VERSION "HIPBNYYYYYYYYYYYYYYYYYYYYYYYYYYYYYYYYYYYYY/4/%%%/4/'%**4YYY///"

NS_ :

BS_:

BU_: RMS_PM_Controller

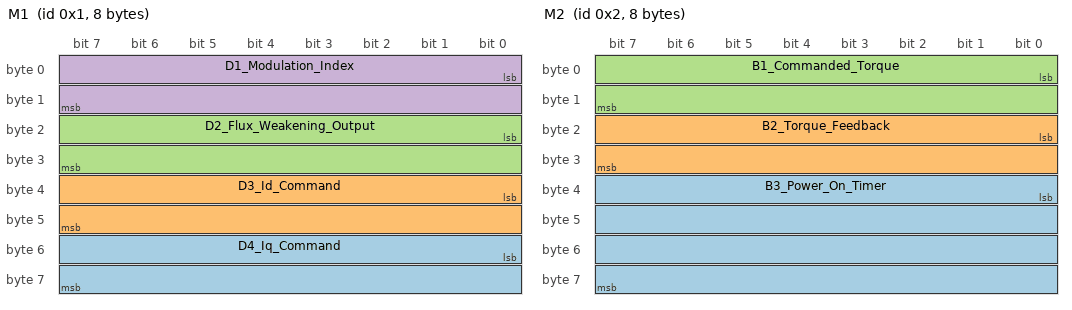
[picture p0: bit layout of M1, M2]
BO_ 1 M1: 8 RMS_PM_Controller
 SG_ D4_Iq_Command : 48|16@1- (0.1,0) [-3276.8|3276.7] "A" Vector__XXX
 SG_ D3_Id_Command : 32|16@1- (0.1,0) [-3276.8|3276.7] "A" Vector__XXX
 SG_ D2_Flux_Weakening_Output : 16|16@1- (0.1,0) [-3276.8|3276.7] "A" Vector__XXX
 SG_ D1_Modulation_Index : 0|16@1+ (0.01,0) [0|0] "" Vector__XXX

BO_ 2 M2: 8 RMS_PM_Controller
 SG_ B3_Power_On_Timer : 32|32@1+ (0.003,0) [0|4.29497e+009] "Sec" Vector__XXX
 SG_ B2_Torque_Feedback : 16|16@1- (0.1,0) [-3276.8|3276.7] "Nm" Vector__XXX
 SG_ B1_Commanded_Torque : 0|16@1- (0.1,0) [-3276.8|3276.7] "Nm" Vector__XXX

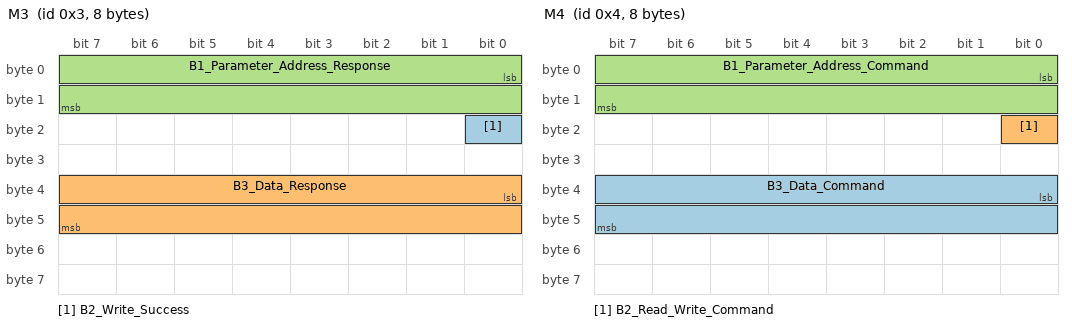
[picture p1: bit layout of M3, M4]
BO_ 3 M3: 8 RMS_PM_Controller
 SG_ B2_Write_Success : 16|1@1+ (1,0) [0|1] "" Vector__XXX
 SG_ B3_Data_Response : 32|16@1- (1,0) [-32768|32767] "" Vector__XXX
 SG_ B1_Parameter_Address_Response : 0|16@1+ (1,0) [0|65535] "" Vector__XXX

BO_ 4 M4: 8 Vector__XXX
 SG_ B3_Data_Command : 32|16@1- (1,0) [-32768|32767] "" Vector__XXX
 SG_ B2_Read_Write_Command : 16|1@1+ (1,0) [0|1] "" Vector__XXX
 SG_ B1_Parameter_Address_Command : 0|16@1+ (1,0) [0|65535] "" Vector__XXX

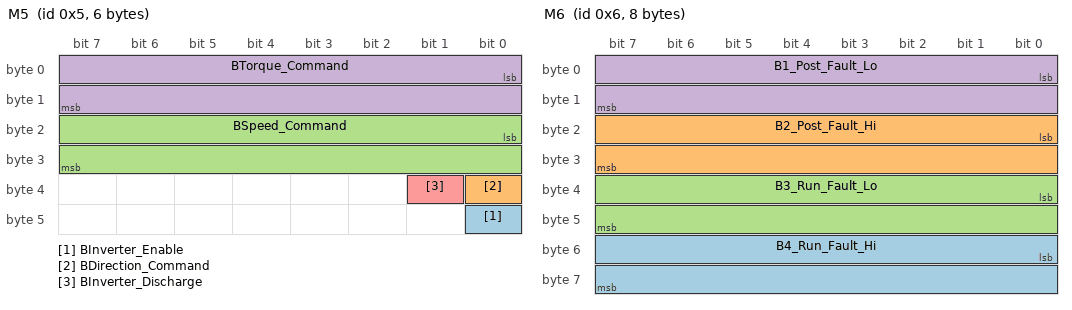
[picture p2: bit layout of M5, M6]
BO_ 5 M5: 6 Vector__XXX
 SG_ BInverter_Enable : 40|1@1+ (1,0) [0|1] "Bit" Vector__XXX
 SG_ BDirection_Command : 32|1@1+ (1,0) [0|1] "Bit" Vector__XXX
 SG_ BSpeed_Command : 16|16@1- (1,0) [-32768|32767] "rpm" Vector__XXX
 SG_ BTorque_Command : 0|16@1- (0.1,0) [-3276.8|3276.7] "Nm" Vector__XXX
 SG_ BInverter_Discharge : 33|1@1+ (1,0) [0|1] "Bit" Vector__XXX

BO_ 6 M6: 8 RMS_PM_Controller
 SG_ B4_Run_Fault_Hi : 48|16@1+ (1,0) [0|65535] "" Vector__XXX
 SG_ B2_Post_Fault_Hi : 16|16@1+ (1,0) [0|65535] "" Vector__XXX
 SG_ B3_Run_Fault_Lo : 32|16@1+ (1,0) [0|65535] "" Vector__XXX
 SG_ B1_Post_Fault_Lo : 0|16@1+ (1,0) [0|65535] "" Vector__XXX

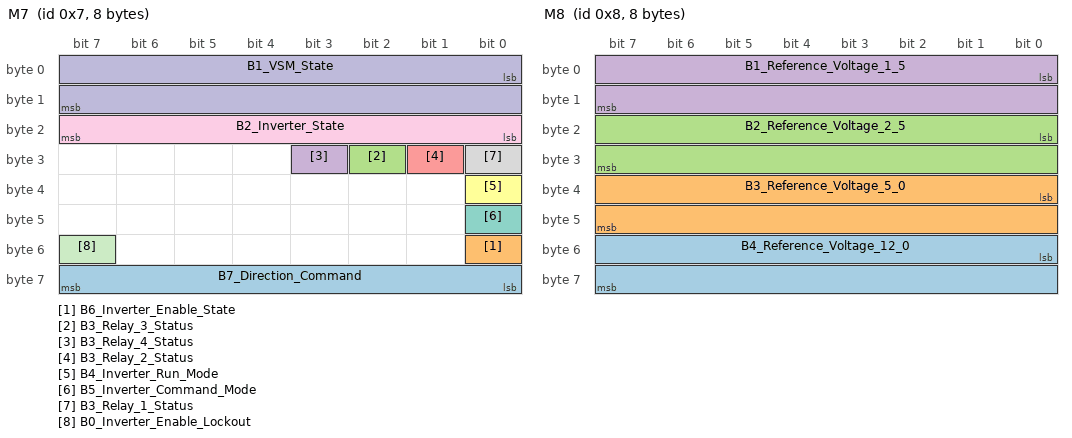
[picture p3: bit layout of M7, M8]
BO_ 7 M7: 8 RMS_PM_Controller
 SG_ B7_Direction_Command : 56|8@1+ (1,0) [0|1] "" Vector__XXX
 SG_ B6_Inverter_Enable_State : 48|1@1+ (1,0) [0|1] "" Vector__XXX
 SG_ B3_Relay_3_Status : 26|1@1+ (1,0) [0|1] "" Vector__XXX
 SG_ B3_Relay_4_Status : 27|1@1+ (1,0) [0|1] "" Vector__XXX
 SG_ B3_Relay_2_Status : 25|1@1+ (1,0) [0|1] "" Vector__XXX
 SG_ B4_Inverter_Run_Mode : 32|1@1+ (1,0) [0|1] "" Vector__XXX
 SG_ B5_Inverter_Command_Mode : 40|1@1+ (1,0) [0|1] "" Vector__XXX
 SG_ B3_Relay_1_Status : 24|1@1+ (1,0) [0|1] "" Vector__XXX
 SG_ B2_Inverter_State : 16|8@1+ (1,0) [0|255] "" Vector__XXX
 SG_ B1_VSM_State : 0|16@1+ (1,0) [0|15] "" Vector__XXX
 SG_ B0_Inverter_Enable_Lockout : 55|1@1+ (1,0) [0|1] "" Vector__XXX

BO_ 8 M8: 8 RMS_PM_Controller
 SG_ B4_Reference_Voltage_12_0 : 48|16@1- (0.01,0) [-327.68|327.67] "V" Vector__XXX
 SG_ B3_Reference_Voltage_5_0 : 32|16@1- (0.01,0) [-327.68|327.67] "V" Vector__XXX
 SG_ B2_Reference_Voltage_2_5 : 16|16@1- (0.01,0) [-327.68|327.67] "V" Vector__XXX
 SG_ B1_Reference_Voltage_1_5 : 0|16@1- (0.01,0) [-327.68|327.67] "V" Vector__XXX

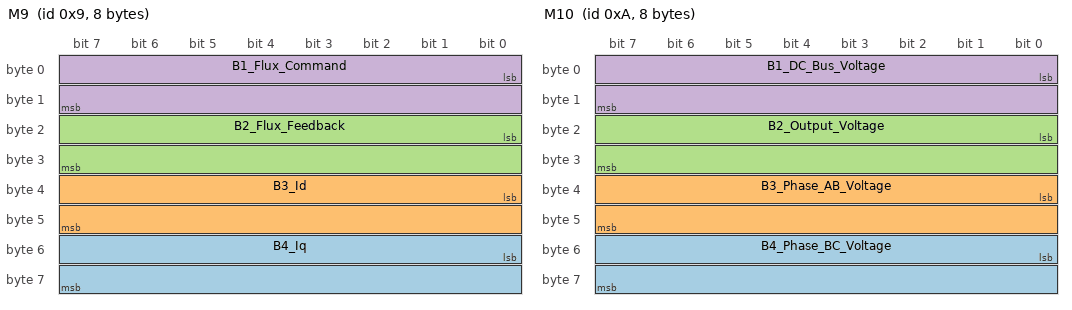
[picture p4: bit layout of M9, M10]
BO_ 9 M9: 8 RMS_PM_Controller
 SG_ B4_Iq : 48|16@1- (0.1,0) [-3276.8|3276.7] "A" Vector__XXX
 SG_ B3_Id : 32|16@1- (0.1,0) [-3276.8|3276.7] "A" Vector__XXX
 SG_ B2_Flux_Feedback : 16|16@1- (0.001,0) [-32.768|32.767] "Wb" Vector__XXX
 SG_ B1_Flux_Command : 0|16@1- (0.001,0) [-32.768|32.767] "Wb" Vector__XXX

BO_ 10 M10: 8 RMS_PM_Controller
 SG_ B4_Phase_BC_Voltage : 48|16@1- (0.1,0) [-3276.8|3276.7] "V" Vector__XXX
 SG_ B3_Phase_AB_Voltage : 32|16@1- (0.1,0) [-3276.8|3276.7] "V" Vector__XXX
 SG_ B2_Output_Voltage : 16|16@1- (0.1,0) [-3276.8|3276.7] "V" Vector__XXX
 SG_ B1_DC_Bus_Voltage : 0|16@1- (0.1,0) [-3276.8|3276.7] "V" Vector__XXX

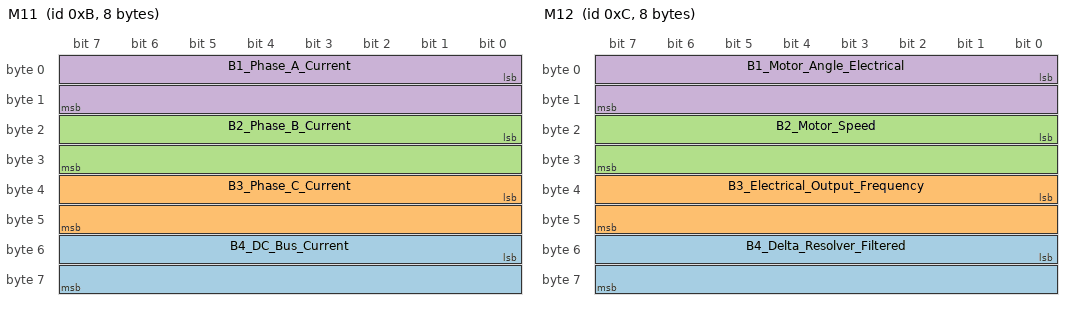
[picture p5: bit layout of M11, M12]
BO_ 11 M11: 8 RMS_PM_Controller
 SG_ B4_DC_Bus_Current : 48|16@1- (0.1,0) [-3276.8|3276.7] "A" Vector__XXX
 SG_ B3_Phase_C_Current : 32|16@1- (0.1,0) [-3276.8|3276.7] "A" Vector__XXX
 SG_ B2_Phase_B_Current : 16|16@1- (0.1,0) [-3276.8|3276.7] "A" Vector__XXX
 SG_ B1_Phase_A_Current : 0|16@1- (0.1,0) [-3276.8|3276.7] "A" Vector__XXX

BO_ 12 M12: 8 RMS_PM_Controller
 SG_ B4_Delta_Resolver_Filtered : 48|16@1- (0.1,0) [-3276.8|3276.7] "deg" Vector__XXX
 SG_ B3_Electrical_Output_Frequency : 32|16@1- (0.1,0) [-3276.8|3276.7] "hz" Vector__XXX
 SG_ B2_Motor_Speed : 16|16@1- (1,0) [-32768|32767] "rpm" Vector__XXX
 SG_ B1_Motor_Angle_Electrical : 0|16@1+ (0.1,0) [0|6553.5] "deg" Vector__XXX

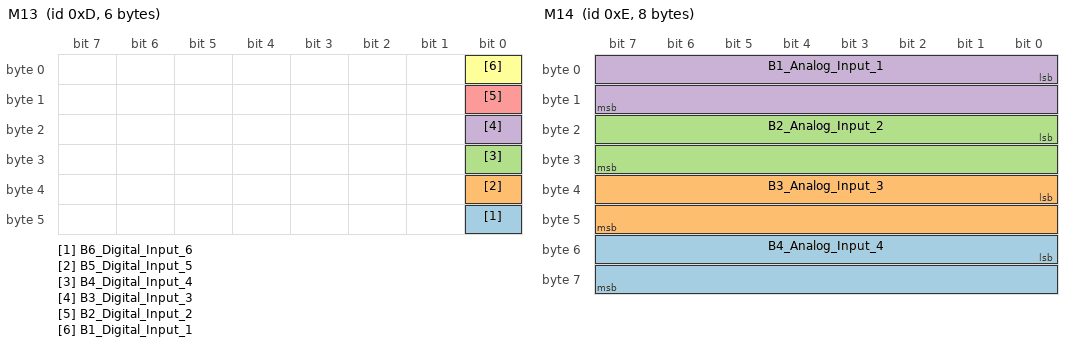
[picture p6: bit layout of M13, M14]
BO_ 13 M13: 6 RMS_PM_Controller
 SG_ B6_Digital_Input_6 : 40|1@1+ (1,0) [0|1] "boolean" Vector__XXX
 SG_ B5_Digital_Input_5 : 32|1@1+ (1,0) [0|1] "boolean" Vector__XXX
 SG_ B4_Digital_Input_4 : 24|1@1+ (1,0) [0|1] "boolean" Vector__XXX
 SG_ B3_Digital_Input_3 : 16|1@1+ (1,0) [0|1] "boolean" Vector__XXX
 SG_ B2_Digital_Input_2 : 8|1@1+ (1,0) [0|1] "boolean" Vector__XXX
 SG_ B1_Digital_Input_1 : 0|1@1+ (1,0) [0|1] "boolean" Vector__XXX

BO_ 14 M14: 8 RMS_PM_Controller
 SG_ B4_Analog_Input_4 : 48|16@1- (0.01,0) [-327.68|327.67] "V" Vector__XXX
 SG_ B3_Analog_Input_3 : 32|16@1- (0.01,0) [-327.68|327.67] "V" Vector__XXX
 SG_ B2_Analog_Input_2 : 16|16@1- (0.01,0) [-327.68|327.67] "V" Vector__XXX
 SG_ B1_Analog_Input_1 : 0|16@1- (0.01,0) [-327.68|327.67] "V" Vector__XXX

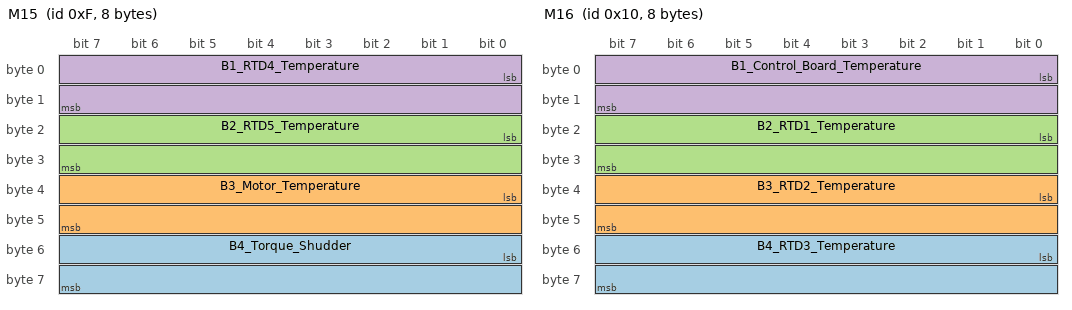
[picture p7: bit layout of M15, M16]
BO_ 15 M15: 8 RMS_PM_Controller
 SG_ B4_Torque_Shudder : 48|16@1- (0.1,0) [-3276.8|3276.7] "Nm" Vector__XXX
 SG_ B3_Motor_Temperature : 32|16@1- (0.1,0) [-3276.8|3276.7] "degC" Vector__XXX
 SG_ B2_RTD5_Temperature : 16|16@1- (0.1,0) [-3276.8|3276.7] "degC" Vector__XXX
 SG_ B1_RTD4_Temperature : 0|16@1- (0.1,0) [-3276.8|3276.7] "degC" Vector__XXX

BO_ 16 M16: 8 RMS_PM_Controller
 SG_ B4_RTD3_Temperature : 48|16@1- (0.1,0) [-3276.8|3276.7] "degC" Vector__XXX
 SG_ B3_RTD2_Temperature : 32|16@1- (0.1,0) [-3276.8|3276.7] "degC" Vector__XXX
 SG_ B2_RTD1_Temperature : 16|16@1- (0.1,0) [-3276.8|3276.7] "degC" Vector__XXX
 SG_ B1_Control_Board_Temperature : 0|16@1- (0.1,0) [-3276.8|3276.7] "degC" Vector__XXX

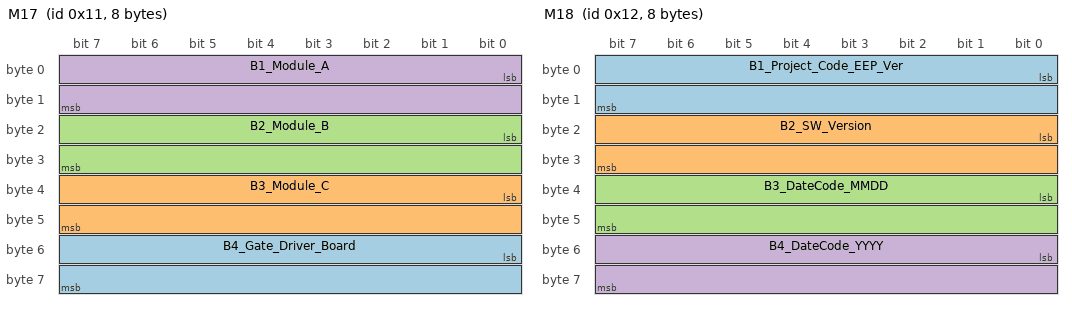
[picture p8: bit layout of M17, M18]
BO_ 17 M17: 8 RMS_PM_Controller
 SG_ B4_Gate_Driver_Board : 48|16@1- (0.1,0) [-3276.8|3276.7] "degC" Vector__XXX
 SG_ B3_Module_C : 32|16@1- (0.1,0) [-3276.8|3276.7] "degC" Vector__XXX
 SG_ B2_Module_B : 16|16@1- (0.1,0) [-3276.8|3276.7] "degC" Vector__XXX
 SG_ B1_Module_A : 0|16@1- (0.1,0) [-3276.8|3276.7] "degC" Vector__XXX

BO_ 18 M18: 8 RMS_PM_Controller
 SG_ B1_Project_Code_EEP_Ver : 0|16@1+ (1,0) [0|65535] "" Vector__XXX
 SG_ B2_SW_Version : 16|16@1+ (1,0) [0|65535] "" Vector__XXX
 SG_ B3_DateCode_MMDD : 32|16@1+ (1,0) [0|65535] "" Vector__XXX
 SG_ B4_DateCode_YYYY : 48|16@1+ (1,0) [0|65535] "" Vector__XXX

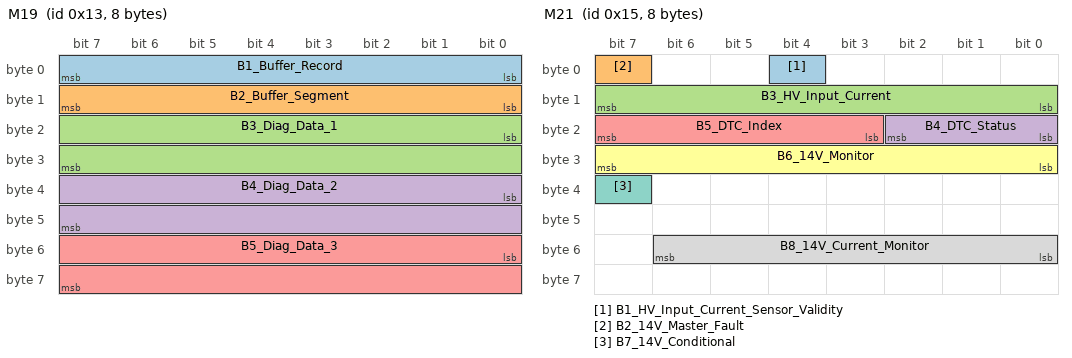
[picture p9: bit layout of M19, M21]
BO_ 19 M19: 8 RMS_PM_Controller
 SG_ B1_Buffer_Record : 0|8@1+ (1,0) [0|160] "" Vector__XXX
 SG_ B2_Buffer_Segment : 8|8@1+ (1,0) [0|5] "" Vector__XXX
 SG_ B3_Diag_Data_1 : 16|16@1- (1,0) [0|65535] "" Vector__XXX
 SG_ B4_Diag_Data_2 : 32|16@1- (1,0) [0|65535] "" Vector__XXX
 SG_ B5_Diag_Data_3 : 48|16@1- (1,0) [0|65535] "" Vector__XXX

BO_ 20 M20: 8 RMS_PM_Controller
 SG_ B1_ID_Byte : 0|8@1+ (1,0) [0|255] "" Vector__XXX
 SG_ B2_Setpoint_Calc : 8|8@1+ (1,0) [0|255] "" Vector__XXX

BO_ 21 M21: 8 Vector__XXX
 SG_ B1_HV_Input_Current_Sensor_Validity : 4|1@1+ (1,0) [0|1] "" Vector__XXX
 SG_ B2_14V_Master_Fault : 7|1@1+ (1,0) [0|1] "" Vector__XXX
 SG_ B3_HV_Input_Current : 8|8@1+ (1,0) [0|255] "" Vector__XXX
 SG_ B4_DTC_Status : 16|3@1+ (1,0) [0|7] "" Vector__XXX
 SG_ B5_DTC_Index : 19|5@1+ (1,0) [0|31] "" Vector__XXX
 SG_ B6_14V_Monitor : 24|8@1+ (1,0) [0|255] "" Vector__XXX
 SG_ B7_14V_Conditional : 39|1@1+ (1,0) [0|1] "" Vector__XXX
 SG_ B8_14V_Current_Monitor : 48|7@1+ (1,0) [0|127] "" Vector__XXX

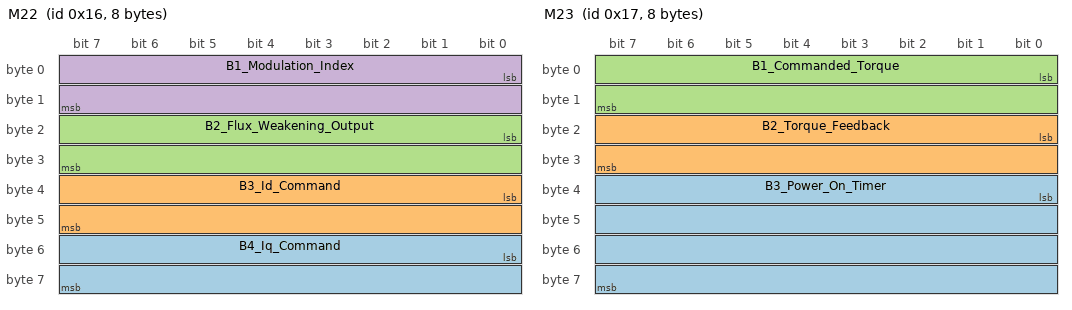
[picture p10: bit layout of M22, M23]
BO_ 22 M22: 8 RMS_PM_Controller
 SG_ B4_Iq_Command : 48|16@1- (0.1,0) [-3276.8|3276.7] "A" Vector__XXX
 SG_ B3_Id_Command : 32|16@1- (0.1,0) [-3276.8|3276.7] "A" Vector__XXX
 SG_ B2_Flux_Weakening_Output : 16|16@1- (0.1,0) [-3276.8|3276.7] "A" Vector__XXX
 SG_ B1_Modulation_Index : 0|16@1+ (0.01,0) [0|0] "" Vector__XXX

BO_ 23 M23: 8 RMS_PM_Controller
 SG_ B3_Power_On_Timer : 32|32@1+ (0.003,0) [0|4.29497e+009] "Sec" Vector__XXX
 SG_ B2_Torque_Feedback : 16|16@1- (0.1,0) [-3276.8|3276.7] "Nm" Vector__XXX
 SG_ B1_Commanded_Torque : 0|16@1- (0.1,0) [-3276.8|3276.7] "Nm" Vector__XXX

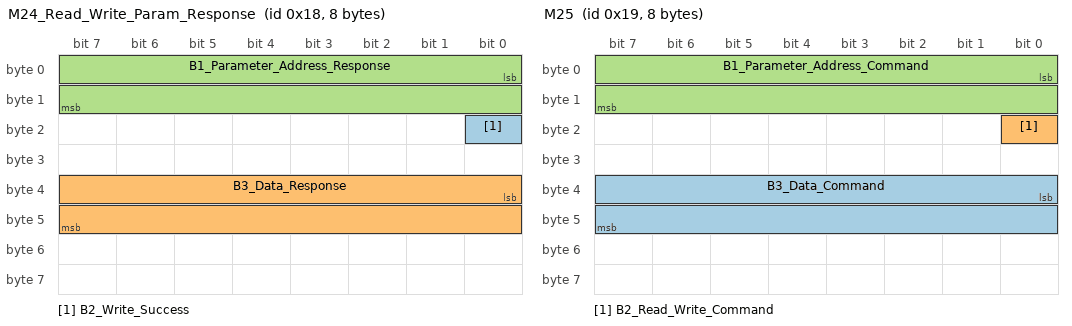
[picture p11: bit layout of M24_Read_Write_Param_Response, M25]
BO_ 24 M24_Read_Write_Param_Response: 8 RMS_PM_Controller
 SG_ B2_Write_Success : 16|1@1+ (1,0) [0|1] "" Vector__XXX
 SG_ B3_Data_Response : 32|16@1- (1,0) [-32768|32767] "" Vector__XXX
 SG_ B1_Parameter_Address_Response : 0|16@1+ (1,0) [0|65535] "" Vector__XXX

BO_ 25 M25: 8 Vector__XXX
 SG_ B3_Data_Command : 32|16@1- (1,0) [-32768|32767] "" Vector__XXX
 SG_ B2_Read_Write_Command : 16|1@1+ (1,0) [0|1] "" Vector__XXX
 SG_ B1_Parameter_Address_Command : 0|16@1+ (1,0) [0|65535] "" Vector__XXX

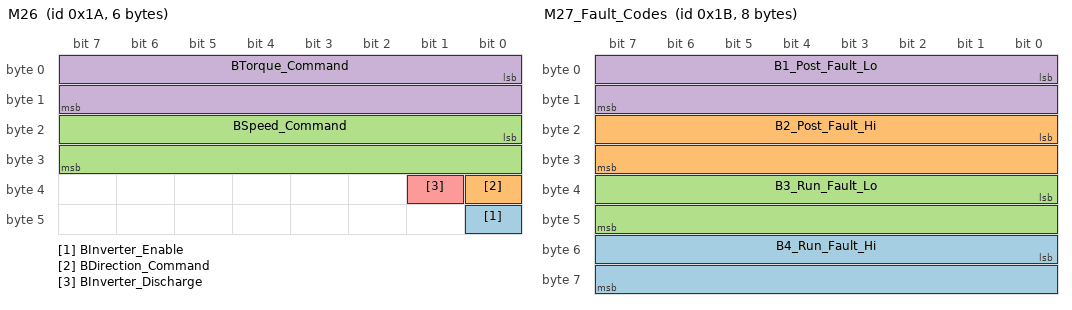
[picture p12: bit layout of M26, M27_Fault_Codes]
BO_ 26 M26: 6 Vector__XXX
 SG_ BInverter_Enable : 40|1@1+ (1,0) [0|1] "Bit" Vector__XXX
 SG_ BDirection_Command : 32|1@1+ (1,0) [0|1] "Bit" Vector__XXX
 SG_ BSpeed_Command : 16|16@1- (1,0) [-32768|32767] "rpm" Vector__XXX
 SG_ BTorque_Command : 0|16@1- (0.1,0) [-3276.8|3276.7] "Nm" Vector__XXX
 SG_ BInverter_Discharge : 33|1@1+ (1,0) [0|1] "Bit" Vector__XXX

BO_ 27 M27_Fault_Codes: 8 RMS_PM_Controller
 SG_ B4_Run_Fault_Hi : 48|16@1+ (1,0) [0|65535] "" Vector__XXX
 SG_ B2_Post_Fault_Hi : 16|16@1+ (1,0) [0|65535] "" Vector__XXX
 SG_ B3_Run_Fault_Lo : 32|16@1+ (1,0) [0|65535] "" Vector__XXX
 SG_ B1_Post_Fault_Lo : 0|16@1+ (1,0) [0|65535] "" Vector__XXX

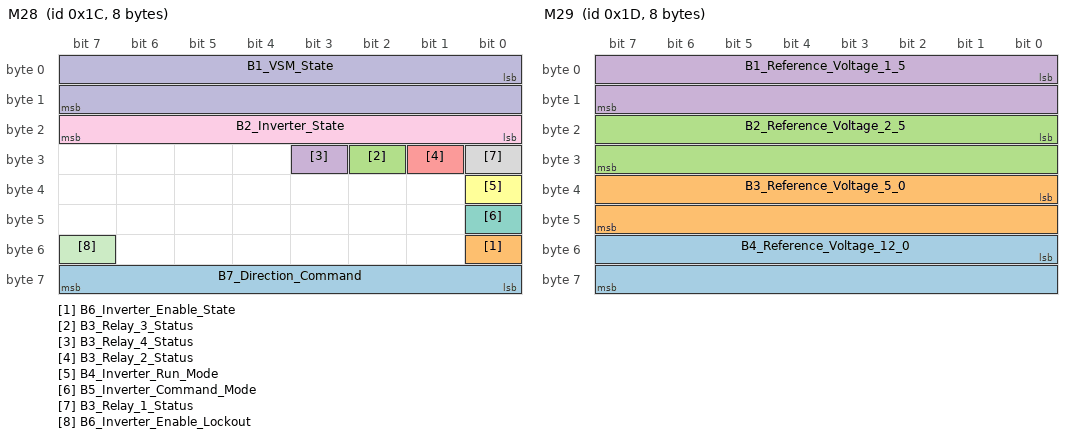
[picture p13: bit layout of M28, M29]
BO_ 28 M28: 8 RMS_PM_Controller
 SG_ B7_Direction_Command : 56|8@1+ (1,0) [0|1] "" Vector__XXX
 SG_ B6_Inverter_Enable_State : 48|1@1+ (1,0) [0|1] "" Vector__XXX
 SG_ B3_Relay_3_Status : 26|1@1+ (1,0) [0|1] "" Vector__XXX
 SG_ B3_Relay_4_Status : 27|1@1+ (1,0) [0|1] "" Vector__XXX
 SG_ B3_Relay_2_Status : 25|1@1+ (1,0) [0|1] "" Vector__XXX
 SG_ B4_Inverter_Run_Mode : 32|1@1+ (1,0) [0|1] "" Vector__XXX
 SG_ B5_Inverter_Command_Mode : 40|1@1+ (1,0) [0|1] "" Vector__XXX
 SG_ B3_Relay_1_Status : 24|1@1+ (1,0) [0|1] "" Vector__XXX
 SG_ B2_Inverter_State : 16|8@1+ (1,0) [0|255] "" Vector__XXX
 SG_ B1_VSM_State : 0|16@1+ (1,0) [0|15] "" Vector__XXX
 SG_ B6_Inverter_Enable_Lockout : 55|1@1+ (1,0) [0|1] "" Vector__XXX

BO_ 29 M29: 8 RMS_PM_Controller
 SG_ B4_Reference_Voltage_12_0 : 48|16@1- (0.01,0) [-327.68|327.67] "V" Vector__XXX
 SG_ B3_Reference_Voltage_5_0 : 32|16@1- (0.01,0) [-327.68|327.67] "V" Vector__XXX
 SG_ B2_Reference_Voltage_2_5 : 16|16@1- (0.01,0) [-327.68|327.67] "V" Vector__XXX
 SG_ B1_Reference_Voltage_1_5 : 0|16@1- (0.01,0) [-327.68|327.67] "V" Vector__XXX

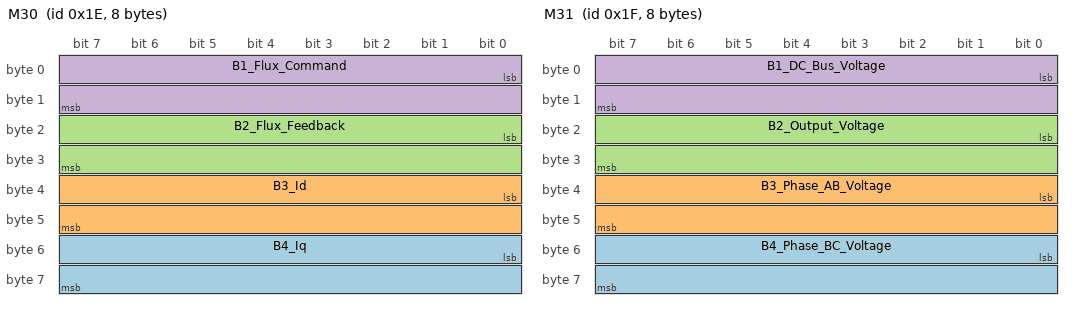
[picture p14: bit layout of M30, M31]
BO_ 30 M30: 8 RMS_PM_Controller
 SG_ B4_Iq : 48|16@1- (0.1,0) [-3276.8|3276.7] "A" Vector__XXX
 SG_ B3_Id : 32|16@1- (0.1,0) [-3276.8|3276.7] "A" Vector__XXX
 SG_ B2_Flux_Feedback : 16|16@1- (0.001,0) [-32.768|32.767] "Wb" Vector__XXX
 SG_ B1_Flux_Command : 0|16@1- (0.001,0) [-32.768|32.767] "Wb" Vector__XXX

BO_ 31 M31: 8 RMS_PM_Controller
 SG_ B4_Phase_BC_Voltage : 48|16@1- (0.1,0) [-3276.8|3276.7] "V" Vector__XXX
 SG_ B3_Phase_AB_Voltage : 32|16@1- (0.1,0) [-3276.8|3276.7] "V" Vector__XXX
 SG_ B2_Output_Voltage : 16|16@1- (0.1,0) [-3276.8|3276.7] "V" Vector__XXX
 SG_ B1_DC_Bus_Voltage : 0|16@1- (0.1,0) [-3276.8|3276.7] "V" Vector__XXX

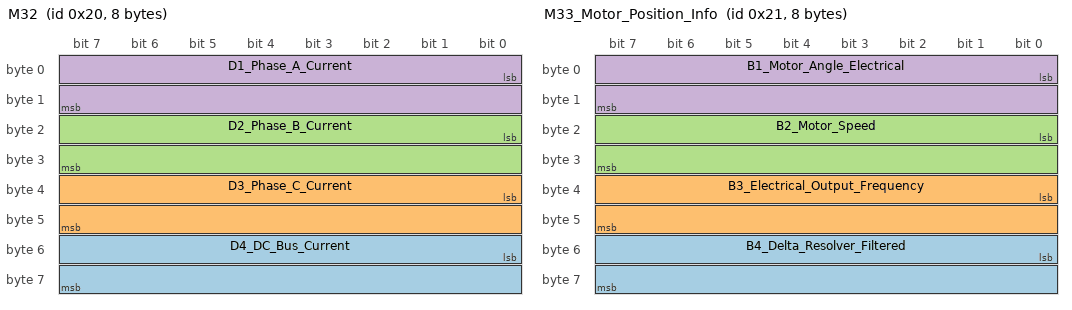
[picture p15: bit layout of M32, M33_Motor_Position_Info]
BO_ 32 M32: 8 RMS_PM_Controller
 SG_ D4_DC_Bus_Current : 48|16@1- (0.1,0) [-3276.8|3276.7] "A" Vector__XXX
 SG_ D3_Phase_C_Current : 32|16@1- (0.1,0) [-3276.8|3276.7] "A" Vector__XXX
 SG_ D2_Phase_B_Current : 16|16@1- (0.1,0) [-3276.8|3276.7] "A" Vector__XXX
 SG_ D1_Phase_A_Current : 0|16@1- (0.1,0) [-3276.8|3276.7] "A" Vector__XXX

BO_ 33 M33_Motor_Position_Info: 8 RMS_PM_Controller
 SG_ B4_Delta_Resolver_Filtered : 48|16@1- (0.1,0) [-3276.8|3276.7] "deg" Vector__XXX
 SG_ B3_Electrical_Output_Frequency : 32|16@1- (0.1,0) [-3276.8|3276.7] "hz" Vector__XXX
 SG_ B2_Motor_Speed : 16|16@1- (1,0) [-32768|32767] "rpm" Vector__XXX
 SG_ B1_Motor_Angle_Electrical : 0|16@1+ (0.1,0) [0|6553.5] "deg" Vector__XXX

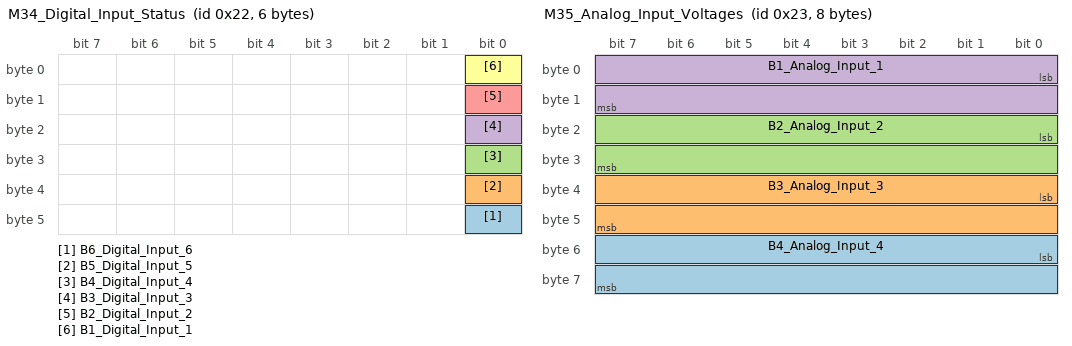
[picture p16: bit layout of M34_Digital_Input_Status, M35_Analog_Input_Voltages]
BO_ 34 M34_Digital_Input_Status: 6 RMS_PM_Controller
 SG_ B6_Digital_Input_6 : 40|1@1+ (1,0) [0|1] "boolean" Vector__XXX
 SG_ B5_Digital_Input_5 : 32|1@1+ (1,0) [0|1] "boolean" Vector__XXX
 SG_ B4_Digital_Input_4 : 24|1@1+ (1,0) [0|1] "boolean" Vector__XXX
 SG_ B3_Digital_Input_3 : 16|1@1+ (1,0) [0|1] "boolean" Vector__XXX
 SG_ B2_Digital_Input_2 : 8|1@1+ (1,0) [0|1] "boolean" Vector__XXX
 SG_ B1_Digital_Input_1 : 0|1@1+ (1,0) [0|1] "boolean" Vector__XXX

BO_ 35 M35_Analog_Input_Voltages: 8 RMS_PM_Controller
 SG_ B4_Analog_Input_4 : 48|16@1- (0.01,0) [-327.68|327.67] "V" Vector__XXX
 SG_ B3_Analog_Input_3 : 32|16@1- (0.01,0) [-327.68|327.67] "V" Vector__XXX
 SG_ B2_Analog_Input_2 : 16|16@1- (0.01,0) [-327.68|327.67] "V" Vector__XXX
 SG_ B1_Analog_Input_1 : 0|16@1- (0.01,0) [-327.68|327.67] "V" Vector__XXX

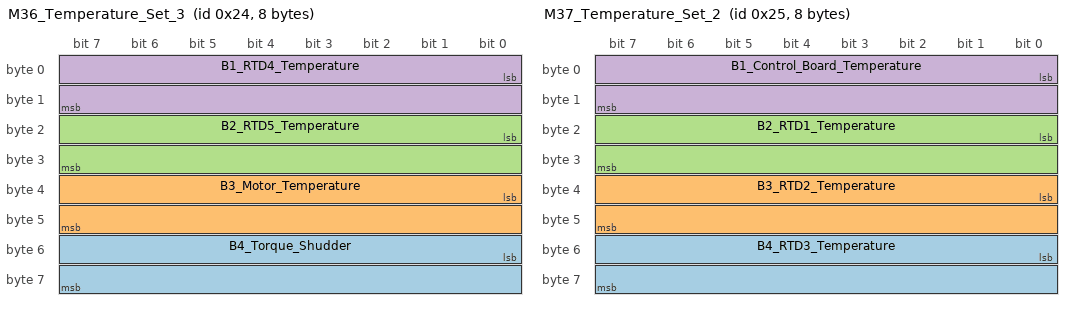
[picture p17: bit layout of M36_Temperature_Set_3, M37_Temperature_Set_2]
BO_ 36 M36_Temperature_Set_3: 8 RMS_PM_Controller
 SG_ B4_Torque_Shudder : 48|16@1- (0.1,0) [-3276.8|3276.7] "Nm" Vector__XXX
 SG_ B3_Motor_Temperature : 32|16@1- (0.1,0) [-3276.8|3276.7] "degC" Vector__XXX
 SG_ B2_RTD5_Temperature : 16|16@1- (0.1,0) [-3276.8|3276.7] "degC" Vector__XXX
 SG_ B1_RTD4_Temperature : 0|16@1- (0.1,0) [-3276.8|3276.7] "degC" Vector__XXX

BO_ 37 M37_Temperature_Set_2: 8 RMS_PM_Controller
 SG_ B4_RTD3_Temperature : 48|16@1- (0.1,0) [-3276.8|3276.7] "degC" Vector__XXX
 SG_ B3_RTD2_Temperature : 32|16@1- (0.1,0) [-3276.8|3276.7] "degC" Vector__XXX
 SG_ B2_RTD1_Temperature : 16|16@1- (0.1,0) [-3276.8|3276.7] "degC" Vector__XXX
 SG_ B1_Control_Board_Temperature : 0|16@1- (0.1,0) [-3276.8|3276.7] "degC" Vector__XXX

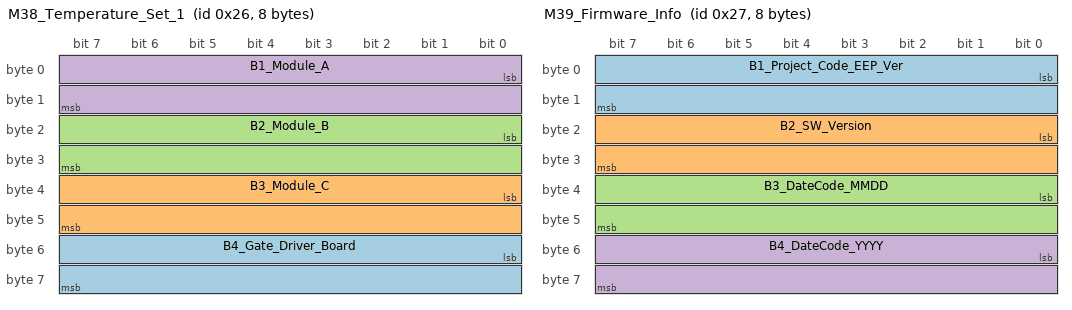
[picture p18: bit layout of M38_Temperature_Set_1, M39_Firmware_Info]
BO_ 38 M38_Temperature_Set_1: 8 RMS_PM_Controller
 SG_ B4_Gate_Driver_Board : 48|16@1- (0.1,0) [-3276.8|3276.7] "degC" Vector__XXX
 SG_ B3_Module_C : 32|16@1- (0.1,0) [-3276.8|3276.7] "degC" Vector__XXX
 SG_ B2_Module_B : 16|16@1- (0.1,0) [-3276.8|3276.7] "degC" Vector__XXX
 SG_ B1_Module_A : 0|16@1- (0.1,0) [-3276.8|3276.7] "degC" Vector__XXX

BO_ 39 M39_Firmware_Info: 8 RMS_PM_Controller
 SG_ B1_Project_Code_EEP_Ver : 0|16@1+ (1,0) [0|65535] "" Vector__XXX
 SG_ B2_SW_Version : 16|16@1+ (1,0) [0|65535] "" Vector__XXX
 SG_ B3_DateCode_MMDD : 32|16@1+ (1,0) [0|65535] "" Vector__XXX
 SG_ B4_DateCode_YYYY : 48|16@1+ (1,0) [0|65535] "" Vector__XXX

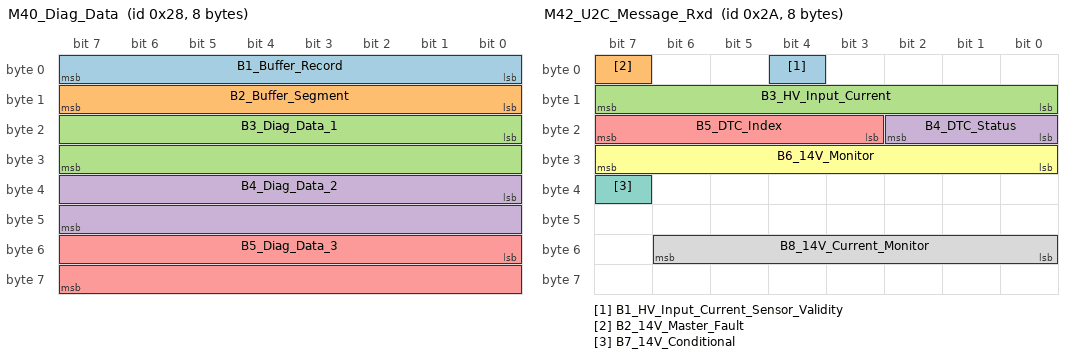
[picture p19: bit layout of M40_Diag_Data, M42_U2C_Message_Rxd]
BO_ 40 M40_Diag_Data: 8 RMS_PM_Controller
 SG_ B1_Buffer_Record : 0|8@1+ (1,0) [0|160] "" Vector__XXX
 SG_ B2_Buffer_Segment : 8|8@1+ (1,0) [0|5] "" Vector__XXX
 SG_ B3_Diag_Data_1 : 16|16@1- (1,0) [0|65535] "" Vector__XXX
 SG_ B4_Diag_Data_2 : 32|16@1- (1,0) [0|65535] "" Vector__XXX
 SG_ B5_Diag_Data_3 : 48|16@1- (1,0) [0|65535] "" Vector__XXX

BO_ 41 M41_U2C_Command_Txd: 8 RMS_PM_Controller
 SG_ B1_ID_Byte : 0|8@1+ (1,0) [0|255] "" Vector__XXX
 SG_ B2_Setpoint_Calc : 8|8@1+ (1,0) [0|255] "" Vector__XXX

BO_ 42 M42_U2C_Message_Rxd: 8 Vector__XXX
 SG_ B1_HV_Input_Current_Sensor_Validity : 4|1@1+ (1,0) [0|1] "" Vector__XXX
 SG_ B2_14V_Master_Fault : 7|1@1+ (1,0) [0|1] "" Vector__XXX
 SG_ B3_HV_Input_Current : 8|8@1+ (1,0) [0|255] "" Vector__XXX
 SG_ B4_DTC_Status : 16|3@1+ (1,0) [0|7] "" Vector__XXX
 SG_ B5_DTC_Index : 19|5@1+ (1,0) [0|31] "" Vector__XXX
 SG_ B6_14V_Monitor : 24|8@1+ (1,0) [0|255] "" Vector__XXX
 SG_ B7_14V_Conditional : 39|1@1+ (1,0) [0|1] "" Vector__XXX
 SG_ B8_14V_Current_Monitor : 48|7@1+ (1,0) [0|127] "" Vector__XXX

CM_ SG_ 173 D4_Iq_Command "The commanded Q-axis current";
CM_ SG_ 173 D3_Id_Command "The commanded D-axis current";
CM_ SG_ 173 D2_Flux_Weakening_Output "This is the current output of the flux regulator.";
CM_ SG_ 173 D1_Modulation_Index "This is the modulation index. The scale factor is x100. To get the actual modulation index divide the value by 100.";
CM_ SG_ 172 D3_Power_On_Timer "Updated every 3 msec. This will roll over in approximately 150 days!";
CM_ SG_ 172 D2_Torque_Feedback "Estimated motor torque feedback";
CM_ SG_ 172 D1_Commanded_Torque "The commanded Torque";
CM_ BO_ 194 "To write a parameter use message 0x0C1 with byte #2 set to 1 (write). 
To read a parameter use message 0x0C1 with byte #2 to set 0 (read). ";
CM_ SG_ 194 D2_Write_Success "0=Write failure, 1=Success";
CM_ SG_ 194 D3_Data_Response "All EEPROM data is 16 bits and is contained in bytes 4 and 5. Bytes 6 and 7 should be ignored.";
CM_ SG_ 194 D1_Parameter_Address_Response "Valid EEPROM Parameter CAN addresses are between 100 and 499.";
CM_ BO_ 193 "To write a parameter use message 0x0C1 with byte #2 set to 1 (write). 
To read a parameter use message 0x0C1 with byte #2 to set 0 (read). ";
CM_ SG_ 193 D3_Data_Command "All EEPROM data is 16 bits and is contained in bytes 4 and 5.";
CM_ SG_ 193 D2_Read_Write_Command "0=Read, 1=Write";
CM_ SG_ 193 D1_Parameter_Address_Command "Valid EEPROM Parameter CAN addresses are between 100 and 499.";
CM_ BO_ 192 "The command message is used to transmit data to the controller. This message is sent from a user supplied external controller to the PMxxx controller.";
CM_ SG_ 192 Inverter_Enable "0=Inverter OFF, 1 = Inverter ON";
CM_ SG_ 192 Direction_Command "0=CW, 1=CCW as veiwed from the shaft end of the motor";
CM_ SG_ 192 Speed_Command "Speed commandused when in speed mode";
CM_ SG_ 192 Torque_Command "Torque command when in torque mode";
CM_ SG_ 192 Inverter_Discharge "0=Discharge Disable,
=Discharge Enable";
CM_ SG_ 171 D4_Run_Fault_Hi "Each bit represents a fault. Please refer to PM100 Users Manual for details.";
CM_ SG_ 171 D2_Post_Fault_Hi "Each bit represents a fault. Please refer to PM100 Users Manual for details.";
CM_ SG_ 171 D3_Run_Fault_Lo "Each bit represents a fault. Please refer to PM100 Users Manual for details.";
CM_ SG_ 171 D1_Post_Fault_Lo "Each bit represents a fault. Please refer to PM100 Users Manual for details.";
CM_ SG_ 170 D7_Direction_Command "1 = Forward
0 = 'Reverse' if inverter enabled  & 'Stopped' if inverter is disabled";
CM_ SG_ 170 D6_Inverter_Enable_State "0=Inverter Disabled, 
1=Inverter Enabled";
CM_ SG_ 170 D3_Relay_3_Status "0=OFF, 1=ON";
CM_ SG_ 170 D3_Relay_4_Status "0=OFF, 1=ON";
CM_ SG_ 170 D3_Relay_2_Status "0=OFF, 1=ON";
CM_ SG_ 170 D4_Inverter_Run_Mode "0=Torque Mode, 1=Speed Mode";
CM_ SG_ 170 D5_Inverter_Command_Mode "0=CAN mode, 1=VSM mode";
CM_ SG_ 170 D3_Relay_1_Status "0=OFF, 1=ON";
CM_ SG_ 170 D2_Inverter_State "Different states for the inverter state machine";
CM_ SG_ 170 D1_VSM_State "Different states for the vehicle state machine";
CM_ SG_ 170 D6_Inverter_Enable_Lockout "0=Lockout Disabled, 1=Lockout Enabled";
CM_ SG_ 168 D2_Flux_Feedback "The estimated flux";
CM_ SG_ 168 D1_Flux_Command "The commanded flux";
CM_ SG_ 167 D4_Phase_BC_Voltage "Measured value of the voltage between Phase B and Phase C";
CM_ SG_ 167 D3_Phase_AB_Voltage "Measured value of the voltage betwen phase A and Phase B";
CM_ SG_ 167 D2_Output_Voltage "The calculated value of the output voltage, in peak line-neutral volts";
CM_ SG_ 167 D1_DC_Bus_Voltage "The actual measured value of the DC bus voltage";
CM_ SG_ 166 D4_DC_Bus_Current "The Calculated DC Bus Current";
CM_ SG_ 166 D3_Phase_C_Current "The measured value of Phase C current";
CM_ SG_ 166 D2_Phase_B_Current "The measured value of Phase B current";
CM_ SG_ 166 D1_Phase_A_Current "The measured value of Phase A current";
CM_ SG_ 165 D4_Delta_Resolver_Filtered "Used in calibration of resolver angle adjustment.";
CM_ SG_ 165 D3_Electrical_Output_Frequency "The actual electrical frequency of the inverter";
CM_ SG_ 165 D2_Motor_Speed "The measured speed of the motor";
CM_ SG_ 165 D1_Motor_Angle_Electrical "The Electrical Angle of the motor as read by the encoder or resolver";
CM_ SG_ 164 D6_Digital_Input_6 "Status of Digital Input #6";
CM_ SG_ 164 D5_Digital_Input_5 "Status of Digital Input #5";
CM_ SG_ 164 D4_Digital_Input_4 "Status of Digital Input #4";
CM_ SG_ 164 D3_Digital_Input_3 "Status of Digital Input #3";
CM_ SG_ 164 D2_Digital_Input_2 "Status of Digital Input #2";
CM_ SG_ 164 D1_Digital_Input_1 "Status of Digital Input #1";
CM_ SG_ 163 D4_Analog_Input_4 "Voltage on Analog Input #4";
CM_ SG_ 163 D3_Analog_Input_3 "Voltage on Analog Input #3";
CM_ SG_ 163 D2_Analog_Input_2 "Voltage on Analog Input #2";
CM_ SG_ 163 D1_Analog_Input_1 "Voltage on Analog Input #1";
CM_ SG_ 162 D4_Torque_Shudder "Shudder compensation value of torque";
CM_ SG_ 162 D3_Motor_Temperature "Motor Temperature Sensor";
CM_ SG_ 162 D2_RTD5_Temperature "RTD 5 (PT1000) Temperature";
CM_ SG_ 162 D1_RTD4_Temperature "RTD 4 (PT1000) Temperature";
CM_ SG_ 161 D4_RTD3_Temperature "RTD input 3 (PT1000) Temperature";
CM_ SG_ 161 D3_RTD2_Temperature "RTD input 2 (PT1000) Temperature";
CM_ SG_ 161 D2_RTD1_Temperature "RTD input 1 (PT1000) Temperature";
CM_ SG_ 161 D1_Control_Board_Temperature "Control Board Temperature";
CM_ SG_ 160 D4_Gate_Driver_Board "Gate Driver Board Temperature";
CM_ SG_ 160 D3_Module_C "IGBT Module C Temperature";
CM_ SG_ 160 D2_Module_B "IGBT Module B Temperature";
CM_ SG_ 160 D1_Module_A "IGBT Module A Temperature";
BA_DEF_ BO_  "GenMsgCycleTime" INT 0 100000;
BA_DEF_  "BusType" STRING ;
BA_DEF_DEF_  "GenMsgCycleTime" 0;
BA_DEF_DEF_  "BusType" "CAN";
BA_ "GenMsgCycleTime" BO_ 172 10;
BA_ "GenMsgCycleTime" BO_ 194 10;
BA_ "GenMsgCycleTime" BO_ 193 10;
BA_ "GenMsgCycleTime" BO_ 192 5;
BA_ "GenMsgCycleTime" BO_ 171 100;
BA_ "GenMsgCycleTime" BO_ 170 100;
BA_ "GenMsgCycleTime" BO_ 169 100;
BA_ "GenMsgCycleTime" BO_ 168 10;
BA_ "GenMsgCycleTime" BO_ 167 10;
BA_ "GenMsgCycleTime" BO_ 166 10;
BA_ "GenMsgCycleTime" BO_ 165 10;
BA_ "GenMsgCycleTime" BO_ 164 10;
BA_ "GenMsgCycleTime" BO_ 163 10;
BA_ "GenMsgCycleTime" BO_ 162 100;
BA_ "GenMsgCycleTime" BO_ 161 100;
BA_ "GenMsgCycleTime" BO_ 160 100;
VAL_ 192 Inverter_Enable 0 "Turn the inverter OFF" 1 "Turn the Inverter ON" ;
VAL_ 192 Direction_Command 0 "CW" 1 "CCW" ;
VAL_ 192 Inverter_Discharge 0 "Discharge Disable" 1 "Discharge Enable (if EEPROM parameter is set)" ;
VAL_ 170 D2_Inverter_State 0 "Power up" 1 "Stop" 2 "Open Loop" 3 "Closed Loop" 4 "Internal State" 5 "Internal State" 6 "Internal State" 7 "Internal State" 8 "Idle Run" 9 "Idle Stop" 10 "Internal State" 11 "Intern State" 12 "Internal State" ;
VAL_ 170 D1_VSM_State 0 "VSM Start State" 1 "Pre-Charge Init state" 2 "pre-charge active state" 3 "pre-charge complete state" 4 "VSM wait state" 5 "VSM ready state" 6 "Motor Running State" 7 "blink fault code state" 14 "Shutdown state for Key Switch Mode 1" 15 "Reset the inverter" ;
